# MM32F3270 register map
File version: 3.01
CPU: CM3 r2p1, selectable endian, MPU, no FPU, 3 interrupt priority bits
Registers are 32-bit, read-write, reset 0x0 unless marked. A register's access mark holds for its fields unless they carry their own. Offsets are from the block's base; [hi:lo] are bit positions.

## CRS — CRS registers
Base 0x40006C00
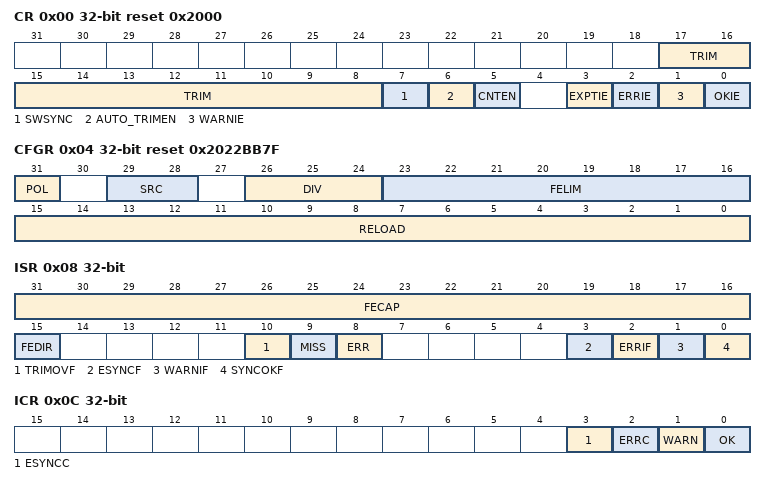
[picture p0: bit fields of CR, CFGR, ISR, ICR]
0x00 CR reset 0x2000 — Control register
  [17:8] TRIM — HSI48 oscillator smooth trimming
  [7] SWSYNC — Generate software SYNC event
  [6] AUTO_TRIMEN — Automatic trimming enable
  [5] CNTEN — Frequency error counter enable
  [3] EXPTIE — Expected SYNC interrupt enable
  [2] ERRIE — Synchronization or trimming error interrupt enable
  [1] WARNIE — SYNC warning interrupt enable
  [0] OKIE — SYNC event OK interrupt enable
0x04 CFGR ro reset 0x2022BB7F — Configuration register
  [31] POL — SYNC polarity selection
  [29:28] SRC — SYNC signal source selection
  [26:24] DIV — SYNC divider
  [23:16] FELIM — Frequency error limit
  [15:0] RELOAD — Counter reload value)
0x08 ISR ro — Interrupt status register
  [31:16] FECAP — Frequency error capture
  [15] FEDIR — Frequency error direction
  [10] TRIMOVF — Trimming overflow or underflow
  [9] MISS — SYNC missed
  [8] ERR — SYNC error
  [3] ESYNCF — Expected SYNC flag
  [2] ERRIF — Error flag
  [1] WARNIF — SYNC warning flag
  [0] SYNCOKF — SYNC event OK flag
0x0C ICR wo — Interrupt clear register
  [3] ESYNCC — Expected SYNC clear flag
  [2] ERRC — Error clear flag
  [1] WARN — SYNC warning clear flag
  [0] OK — SYNC event OK clear flag

## DAC — Digital to analog converter
Base 0x40007400
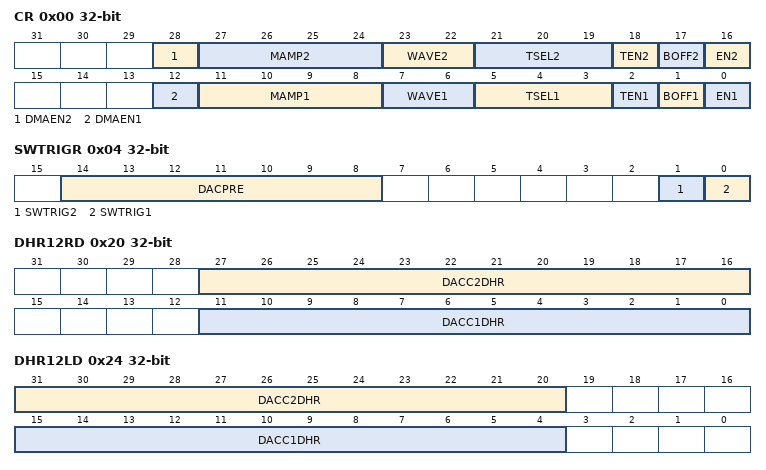
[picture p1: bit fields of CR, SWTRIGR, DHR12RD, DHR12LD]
0x00 CR — Control register
  [28] DMAEN2 — DAC channel2 DMA enable
  [27:24] MAMP2 — DAC channel2 mask/amplitude selector
  [23:22] WAVE2 — DAC channel2 noise/triangle wave generation enable
  [21:19] TSEL2 — DAC channel2 trigger selection
  [18] TEN2 — DAC channel2 trigger enable
  [17] BOFF2 — DAC channel2 output buffer disable
  [16] EN2 — DAC channel2 enable
  [12] DMAEN1 — DAC channel1 DMA enable
  [11:8] MAMP1 — DAC channel1 mask/amplitude selector
  [7:6] WAVE1 — DAC channel1 noise/triangle wave generation enable
  [5:3] TSEL1 — DAC channel1 trigger selection
  [2] TEN1 — DAC channel1 trigger enable
  [1] BOFF1 — DAC channel1 output buffer disable
  [0] EN1 — DAC channel1 enable
0x04 SWTRIGR wo — Software trigger register
  [14:8] DACPRE — DAC prescale
  [1] SWTRIG2 — DAC channel2 software trigger
  [0] SWTRIG1 — DAC channel1 software trigger
0x08 DHR12R1 — Channel1 12-bit right aligned data holding register
  [11:0] DACC1DHR — DAC channel1 12-bit right-aligned data
0x0C DHR12L1 — Channel1 12-bit left aligned data holding register
  [15:4] DACC1DHR — DAC channel1 12-bit left aligned data
0x10 DHR8R1 — Channel1 8-bit right aligned data holding register
  [7:0] DACC1DHR — DAC channel1 8-bit right-aligned data
0x14 DHR12R2 — Channel2 12-bit right aligned data holding register
  [11:0] DACC2DHR — DAC channel2 12-bit right-aligned data
0x18 DHR12L2 — Channel2 12-bit left aligned data holding register
  [15:4] DACC2DHR — DAC channel2 12-bit left-aligned data
0x1C DHR8R2 — Channel2 8-bit right aligned data holding register
  [7:0] DACC2DHR — DAC channel2 8-bit right-aligned data
0x20 DHR12RD — Dual channel 12-bit right aligned data holding register
  [27:16] DACC2DHR — DAC channel2 12-bit right-aligned data
  [11:0] DACC1DHR — DAC channel1 12-bit right-aligned data
0x24 DHR12LD — Dual channel 12-bit left aligned data holding register
  [31:20] DACC2DHR — DAC channel2 12-bit left-aligned data
  [15:4] DACC1DHR — DAC channel1 12-bit left-aligned data
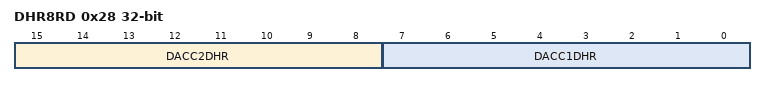
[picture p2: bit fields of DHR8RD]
0x28 DHR8RD — Dual channel 8-bit right aligned data holding register
  [15:8] DACC2DHR — DAC channel2 8-bit right-aligned data
  [7:0] DACC1DHR — DAC channel1 8-bit right-aligned data
0x2C DOR1 — Channel1 data output register
  [11:0] DACC1DOR — DAC channel1 data output
0x30 DOR2 — Channel2 data output register
  [11:0] DACC2DOR — DAC channel2 data output
